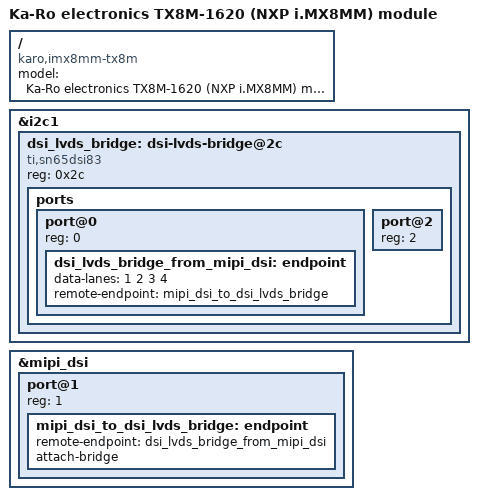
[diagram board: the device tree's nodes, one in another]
// SPDX-License-Identifier: (GPL-2.0 OR MIT)
/*
 * Copyright (C) 2019 Markus Bauer <MB@KARO-electronics.de>
 *
 */

/dts-v1/;

#include "imx8mm-tx8m.dtsi"

/ {
	model = "Ka-Ro electronics TX8M-1620 (NXP i.MX8MM) module";
	compatible = "karo,imx8mm-tx8m", "fsl,imx8mm";
};

&i2c1 {
	dsi_lvds_bridge: dsi-lvds-bridge@2c {
		compatible = "ti,sn65dsi83";
		reg = <0x2c>;

		ports {
			#address-cells = <1>;
			#size-cells = <0>;

			port@0 {
				reg = <0>;

				dsi_lvds_bridge_from_mipi_dsi: endpoint {
					data-lanes = <1 2 3 4>;
					remote-endpoint = <&mipi_dsi_to_dsi_lvds_bridge>;
				};

			};

			port@2 {
				reg = <2>;
			};
		};
	};
};

&mipi_dsi {
	port@1 {
		reg = <1>;

		mipi_dsi_to_dsi_lvds_bridge: endpoint {
			remote-endpoint = <&dsi_lvds_bridge_from_mipi_dsi>;
			attach-bridge;
		};
	};
};
